# STM32H573 register map
File version: 1.8
CPU: CM33 r0p0, little endian, MPU, FPU, 4 interrupt priority bits
Registers are 32-bit, read-write, reset 0x0 unless marked. A register's access mark holds for its fields unless they carry their own. Offsets are from the block's base; [hi:lo] are bit positions; {n}, {i} and the like mark numbered series; 'fields as' and 'values as' point back to an identical list.

## FMC — Flexible memory controller
Base 0x47000400
Same registers: SEC_FMC 0x57000400
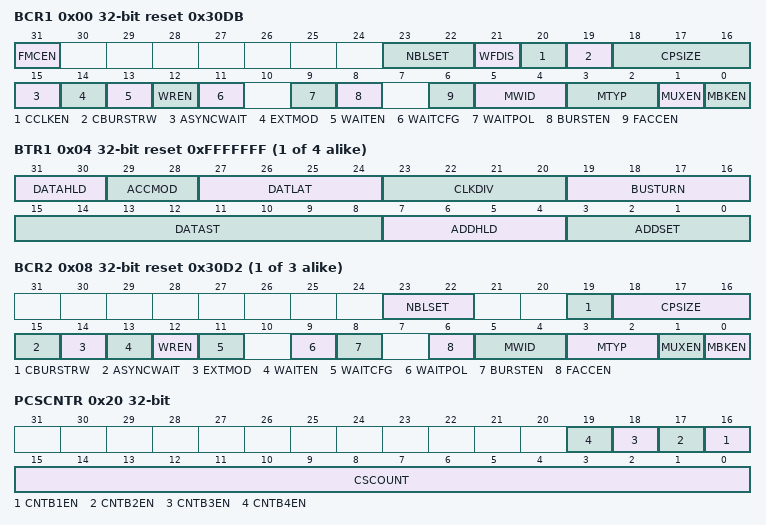
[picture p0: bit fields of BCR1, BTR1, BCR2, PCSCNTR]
0x00 BCR1 reset 0x30DB — SRAM/NOR-Flash chip-select control register for bank 1
  [31] FMCEN — FMC controller enable This bit enables or disables the FMC controller. Note: The FMCEN bit of the FMC_BCR2..4 registers is don't care. It is only enabled through the FMC_BCR1 register.
    0=Disabled (Disable the FMC controller); 1=Enabled (Enable the FMC controller)
  [23:22] NBLSET — Byte lane (NBL) setup These bits configure the NBL setup timing from NBLx low to chip select NEx low.
  [21] WFDIS — Write FIFO disable This bit disables the Write FIFO used by the FMC controller. Note: The WFDIS bit of the FMC_BCR2..4 registers is don't care. It is only enabled through the FMC_BCR1 register.
    0=Enabled (Write FIFO enabled); 1=Disabled (Write FIFO disabled)
  [20] CCLKEN — Continuous clock enable This bit enables the FMC_CLK clock output to external memory devices. Note: The CCLKEN bit of the FMC_BCR2..4 registers is don't care. It is only enabled through the FMC_BCR1 register. Bank 1 must be configured in Synchronous mode to generate the FMC_CLK continuous clock. Note: If CCLKEN bit is set, the FMC_CLK clock ratio is specified by CLKDIV value in the FMC_BTR1 register. CLKDIV in FMC_BWTR1 is don't care. Note: If the Synchronous mode is used and CCLKEN bit is set, the synchronous memories connected to other banks than Bank 1 are clocked by the same clock (the CLKDIV value in the FMC_BTR2..4 and FMC_BWTR2..4 registers for other banks has no effect.)
    0=Disabled (The FMC_CLK is generated continuously during asynchronous and synchronous access. The FMC_CLK clock is activated when the CCLKEN is set); 1=Enabled (The FMC_CLK is only generated during the synchronous memory access (read/write transaction))
  [19] CBURSTRW — Write burst enable For PSRAM (CRAM) operating in Burst mode, the bit enables synchronous accesses during write operations. The enable bit for synchronous read accesses is the BURSTEN bit in the FMC_BCRx register.
    0=Disabled (Write operations are always performed in asynchronous mode); 1=Enabled (Write operations are performed in synchronous mode)
  [18:16] CPSIZE — CRAM page size These are used for CellularRAM 1.5 which does not allow burst access to cross the address boundaries between pages. When these bits are configured, the FMC controller splits automatically the burst access when the memory page size is reached (refer to memory datasheet for page size). Others: reserved
    0=No burst split when crossing page boundary; 1=Bytes128 (128 bytes CRAM page size); 2=Bytes256 (256 bytes CRAM page size); 3=Bytes512 (512 bytes CRAM page size); 4=Bytes1024 (1024 bytes CRAM page size)
  [15] ASYNCWAIT — Wait signal during asynchronous transfers This bit enables/disables the FMC to use the wait signal even during an asynchronous protocol.
    0=Disabled (Wait signal not used in asynchronous mode); 1=Enabled (Wait signal used even in asynchronous mode)
  [14] EXTMOD — Extended mode enable This bit enables the FMC to program the write timings for non multiplexed asynchronous accesses inside the FMC_BWTR register, thus resulting in different timings for read and write operations. Note: When the Extended mode is disabled, the FMC can operate in mode 1 or mode 2 as follows: Mode 1 is the default mode when the SRAM/PSRAM memory type is selected (MTYP = 0x0 or 0x01) Mode 2 is the default mode when the NOR memory type is selected (MTYP = 0x10).
    0=Disabled (Values inside the FMC_BWTR are not taken into account); 1=Enabled (Values inside the FMC_BWTR are taken into account)
  [13] WAITEN — Wait enable bit This bit enables/disables wait-state insertion via the NWAIT signal when accessing the memory in Synchronous mode.
    0=Disabled (Values inside the FMC_BWTR are taken into account); 1=Enabled (NWAIT signal enabled)
  [12] WREN — Write enable bit This bit indicates whether write operations are enabled/disabled in the bank by the FMC.
    0=Disabled (Write operations disabled for the bank by the FMC); 1=Enabled (Write operations enabled for the bank by the FMC)
  [11] WAITCFG — Wait timing configuration The NWAIT signal indicates whether the data from the memory are valid or if a wait state must be inserted when accessing the memory in Synchronous mode. This configuration bit determines if NWAIT is asserted by the memory one clock cycle before the wait state or during the wait state:
    0=BeforeWaitState (NWAIT signal is active one data cycle before wait state); 1=DuringWaitState (NWAIT signal is active during wait state)
  [9] WAITPOL — Wait signal polarity bit Defines the polarity of the wait signal from memory used for either in Synchronous or Asynchronous mode.
    0=ActiveLow (NWAIT active low); 1=ActiveHigh (NWAIT active high)
  [8] BURSTEN — Burst enable bit This bit enables/disables synchronous accesses during read operations. It is valid only for synchronous memories operating in Burst mode.
    0=Disabled (Burst mode disabled); 1=Enabled (Burst mode enabled)
  [6] FACCEN — Flash access enable Enables NOR Flash memory access operations.
    0=Disabled (Corresponding NOR Flash memory access is disabled); 1=Enabled (Corresponding NOR Flash memory access is enabled)
  [5:4] MWID — Memory data bus width Defines the external memory device width, valid for all type of memories.
    0=Bits8 (Memory data bus width 8 bits); 1=Bits16 (Memory data bus width 16 bits); 2=Bits32 (Memory data bus width 32 bits)
  [3:2] MTYP — Memory type Defines the type of external memory attached to the corresponding memory bank.
    0=SRAM (SRAM memory type); 1=PSRAM (PSRAM (CRAM) memory type); 2=Flash (NOR Flash/OneNAND Flash)
  [1] MUXEN — Address/data multiplexing enable bit When this bit is set, the address and data values are multiplexed on the data bus, valid only with NOR and PSRAM memories:
    0=Disabled (Address/Data non-multiplexed); 1=Enabled (Address/Data multiplexed on databus)
  [0] MBKEN — Memory bank enable bit Enables the memory bank. After reset Bank1 is enabled, all others are disabled. Accessing a disabled bank causes an ERROR on AHB bus.
    0=Disabled (Corresponding memory bank is disabled); 1=Enabled (Corresponding memory bank is enabled)
0x04 BTR{i} (i=1..4; step 0x8) reset 0xFFFFFFF — SRAM/NOR-Flash chip-select timing register for bank {i}
  [31:30] DATAHLD — Data hold phase duration These bits are written by software to define the duration of the data hold phase in HCLK cycles (refer to Figure 21 to Figure 33), used in asynchronous accesses: For read accesses For write accesses
  [29:28] ACCMOD — Access mode Specifies the asynchronous access modes as shown in the timing diagrams. These bits are taken into account only when the EXTMOD bit in the FMC_BCRx register is 1.
    0=A (Access mode A); 1=B (Access mode B); 2=C (Access mode C); 3=D (Access mode D)
  [27:24] DATLAT — (see note below bit descriptions): Data latency for synchronous memory For synchronous access with read/write Burst mode enabled (BURSTEN / CBURSTRW bits set), defines the number of memory clock cycles (+2) to issue to the memory before reading/writing the first data: This timing parameter is not expressed in HCLK periods, but in FMC_CLK periods. For asynchronous access, this value is don't care.
  [23:20] CLKDIV range 1..15 — Clock divide ratio (for FMC_CLK signal) Defines the period of FMC_CLK clock output signal, expressed in number of HCLK cycles: In asynchronous NOR Flash, SRAM or PSRAM accesses, this value is don't care. Note: Refer to Section 5.6.5: Synchronous transactions for FMC_CLK divider ratio formula)
  [19:16] BUSTURN — Bus turnaround phase duration These bits are written by software to add a delay at the end of current read or write transaction to next transaction on the same bank. This delay allows to match the minimum time between consecutive transactions (t sub EHEL /sub from NEx high to NEx low) and the maximum time needed by the memory to free the data bus after a read access (t sub EHQZ /sub , chip enable high to output Hi-Z). This delay is recommended for mode D and muxed mode. For non-muxed memory, the bus turnaround delay can be set to minimum value. (BUSTURN + 1)HCLK period greater than or equal max(t sub EHEL /sub min, t sub EHQZ /sub max) For FRAM memories, the bus turnaround delay should be configured to match the minimum tPC (precharge time) timings. The bus turnaround delay is inserted between any consecutive transactions on the same bank (read/read, write/write, read/write and write/read) to match the tPC memory timing. The chip select is toggling between any consecutive accesses. (BUSTURN + 1)HCLK period greater than or equal t sub PC /sub min ...
  [15:8] DATAST range 1..255 — Data-phase duration These bits are written by software to define the duration of the data phase (refer to Figure 21 to Figure 33), used in asynchronous accesses: ... For each memory type and access mode data-phase duration, refer to the respective figure (Figure 21 to Figure 33). Example: Mode 1, write access, DATAST=1: Data-phase duration= DATAST+1 = 2 HCLK clock cycles. Note: In synchronous accesses, this value is don't care.
  [7:4] ADDHLD range 1..15 — Address-hold phase duration These bits are written by software to define the duration of the address hold phase (refer to Figure 21 to Figure 33), used in mode D or multiplexed accesses: ... For each access mode address-hold phase duration, refer to the respective figure (Figure 21 to Figure 33). Note: In synchronous accesses, this value is not used, the address hold phase is always 1 memory clock period duration.
  [3:0] ADDSET — Address setup phase duration These bits are written by software to define the duration of the address setup phase (refer to Figure 21 to Figure 33), used in SRAMs, ROMs, asynchronous NOR Flash and PSRAM: ... For each access mode address setup phase duration, refer to the respective figure (Figure 21 to Figure 33). Note: In synchronous accesses, this value is don't care. Note: In Muxed mode or mode D, the minimum value for ADDSET is 1. Note: In mode 1 and PSRAM memory, the minimum value for ADDSET is 1.
0x08 BCR{i} (i=2..4; step 0x8) reset 0x30D2 — SRAM/NOR-Flash chip-select control register for bank {i}
  [23:22] NBLSET — Byte lane (NBL) setup These bits configure the NBL setup timing from NBLx low to chip select NEx low.
  [19] CBURSTRW — Write burst enable For PSRAM (CRAM) operating in Burst mode, the bit enables synchronous accesses during write operations. The enable bit for synchronous read accesses is the BURSTEN bit in the FMC_BCRx register.
    values as BCR1.CBURSTRW
  [18:16] CPSIZE — CRAM page size These are used for CellularRAM 1.5 which does not allow burst access to cross the address boundaries between pages. When these bits are configured, the FMC controller splits automatically the burst access when the memory page size is reached (refer to memory datasheet for page size). Others: reserved
    values as BCR1.CPSIZE
  [15] ASYNCWAIT — Wait signal during asynchronous transfers This bit enables/disables the FMC to use the wait signal even during an asynchronous protocol.
    values as BCR1.ASYNCWAIT
  [14] EXTMOD — Extended mode enable This bit enables the FMC to program the write timings for non multiplexed asynchronous accesses inside the FMC_BWTR register, thus resulting in different timings for read and write operations. Note: When the Extended mode is disabled, the FMC can operate in mode 1 or mode 2 as follows: Mode 1 is the default mode when the SRAM/PSRAM memory type is selected (MTYP = 0x0 or 0x01) Mode 2 is the default mode when the NOR memory type is selected (MTYP = 0x10).
    values as BCR1.EXTMOD
  [13] WAITEN — Wait enable bit This bit enables/disables wait-state insertion via the NWAIT signal when accessing the memory in Synchronous mode.
    values as BCR1.WAITEN
  [12] WREN — Write enable bit This bit indicates whether write operations are enabled/disabled in the bank by the FMC.
    values as BCR1.WREN
  [11] WAITCFG — Wait timing configuration The NWAIT signal indicates whether the data from the memory are valid or if a wait state must be inserted when accessing the memory in Synchronous mode. This configuration bit determines if NWAIT is asserted by the memory one clock cycle before the wait state or during the wait state:
    values as BCR1.WAITCFG
  [9] WAITPOL — Wait signal polarity bit Defines the polarity of the wait signal from memory used for either in Synchronous or Asynchronous mode.
    values as BCR1.WAITPOL
  [8] BURSTEN — Burst enable bit This bit enables/disables synchronous accesses during read operations. It is valid only for synchronous memories operating in Burst mode.
    values as BCR1.BURSTEN
  [6] FACCEN — Flash access enable Enables NOR Flash memory access operations.
    values as BCR1.FACCEN
  [5:4] MWID — Memory data bus width Defines the external memory device width, valid for all type of memories.
    values as BCR1.MWID
  [3:2] MTYP — Memory type Defines the type of external memory attached to the corresponding memory bank.
    values as BCR1.MTYP
  [1] MUXEN — Address/data multiplexing enable bit When this bit is set, the address and data values are multiplexed on the data bus, valid only with NOR and PSRAM memories:
    values as BCR1.MUXEN
  [0] MBKEN — Memory bank enable bit Enables the memory bank. After reset Bank1 is enabled, all others are disabled. Accessing a disabled bank causes an ERROR on AHB bus.
    values as BCR1.MBKEN
0x20 PCSCNTR — PSRAM chip select counter register
  [n+15] CNTB{n}EN (n=1..4) — Counter Bank {n} enable
  [15:0] CSCOUNT — Chip select counter. These bits are written by software to define the maximum chip select low pulse duration. It is expressed in FMC_CLK cycles for synchronous accesses and in HCLK cycles for asynchronous accesses. The counter is disabled if the programmed value is 0.
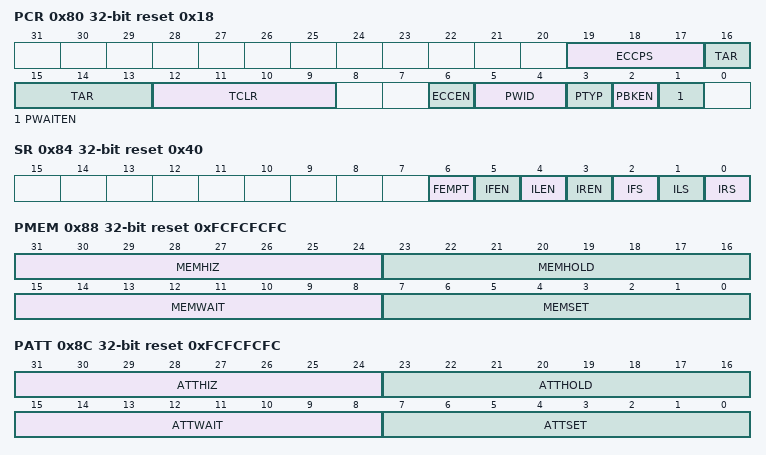
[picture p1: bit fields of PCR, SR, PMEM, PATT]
0x80 PCR access not given reset 0x18 — NAND Flash control registers
  [19:17] ECCPS rw — ECC page size Defines the page size for the extended ECC:
    0=Bytes256 (ECC page size 256 bytes); 1=Bytes512 (ECC page size 512 bytes); 2=Bytes1024 (ECC page size 1024 bytes); 3=Bytes2048 (ECC page size 2048 bytes); 4=Bytes4096 (ECC page size 4096 bytes); 5=Bytes8192 (ECC page size 8192 bytes)
  [16:13] TAR — ALE to RE delay Sets time from ALE low to RE low in number of AHB clock cycles (HCLK). Time is: t_ar = (TAR + SET + 2) THCLK where THCLK is the HCLK clock period Note: SET is MEMSET or ATTSET according to the addressed space.
  [12:9] TCLR rw — CLE to RE delay Sets time from CLE low to RE low in number of AHB clock cycles (HCLK). Time is t_clr = (TCLR + SET + 2) THCLK where THCLK is the HCLK clock period Note: SET is MEMSET or ATTSET according to the addressed space.
  [6] ECCEN rw — ECC computation logic enable bit
    0=Disabled (ECC logic is disabled and reset); 1=Enabled (ECC logic is enabled)
  [5:4] PWID rw — Data bus width Defines the external memory device width.
    0=Bits8 (External memory device width 8 bits); 1=Bits16 (External memory device width 16 bits)
  [3] PTYP rw — Memory type Defines the type of device attached to the corresponding memory bank:
    1=NANDFlash
  [2] PBKEN rw — NAND Flash memory bank enable bit Enables the memory bank. Accessing a disabled memory bank causes an ERROR on AHB bus
    values as BCR1.MBKEN
  [1] PWAITEN rw — Wait feature enable bit Enables the Wait feature for the NAND Flash memory bank:
    0=Disabled (Wait feature disabled); 1=Enabled (Wait feature enabled)
0x84 SR access per field reset 0x40 — FIFO status and interrupt register
  [6] FEMPT ro — FIFO empty Read-only bit that provides the status of the FIFO
    0=NotEmpty (FIFO not empty); 1=Empty (FIFO empty)
  [5] IFEN rw — Interrupt falling edge detection enable bit
    0=Disabled (Interrupt falling edge detection request disabled); 1=Enabled (Interrupt falling edge detection request enabled)
  [4] ILEN rw — Interrupt high-level detection enable bit
    0=Disabled (Interrupt high-level detection request disabled); 1=Enabled (Interrupt high-level detection request enabled)
  [3] IREN rw — Interrupt rising edge detection enable bit
    0=Disabled (Interrupt rising edge detection request disabled); 1=Enabled (Interrupt rising edge detection request enabled)
  [2] IFS rw — Interrupt falling edge status The flag is set by hardware and reset by software. Note: If this bit is written by software to 1 it is set.
    0=DidNotOccur (Interrupt falling edge did not occur); 1=Occurred (Interrupt falling edge occurred)
  [1] ILS rw — Interrupt high-level status The flag is set by hardware and reset by software.
    0=DidNotOccur (Interrupt high-level did not occur); 1=Occurred (Interrupt high-level occurred)
  [0] IRS rw — Interrupt rising edge status The flag is set by hardware and reset by software. Note: If this bit is written by software to 1 it is set.
    0=DidNotOccur (Interrupt rising edge did not occur); 1=Occurred (Interrupt rising edge occurred)
0x88 PMEM reset 0xFCFCFCFC — Common memory space timing register
  [31:24] MEMHIZ range 0..254 — Common memory x data bus Hi-Z time Defines the number of HCLK clock cycles during which the data bus is kept Hi-Z after the start of a NAND Flash write access to common memory space on socket. This is only valid for write transactions:
  [23:16] MEMHOLD range 1..254 — Common memory hold time Defines the number of HCLK clock cycles for write access and HCLK (+2) clock cycles for read access during which the address is held (and data for write accesses) after the command is deasserted (NWE, NOE), for NAND Flash read or write access to common memory space on socket x:
  [15:8] MEMWAIT range 1..254 — Common memory wait time Defines the minimum number of HCLK (+1) clock cycles to assert the command (NWE, NOE), for NAND Flash read or write access to common memory space on socket. The duration of command assertion is extended if the wait signal (NWAIT) is active (low) at the end of the programmed value of HCLK:
  [7:0] MEMSET range 0..254 — Common memory x setup time Defines the number of HCLK (+1) clock cycles to set up the address before the command assertion (NWE, NOE), for NAND Flash read or write access to common memory space on socket x:
0x8C PATT reset 0xFCFCFCFC — Attribute memory space timing register
  [31:24] ATTHIZ range 0..254 — Attribute memory data bus Hi-Z time Defines the number of HCLK clock cycles during which the data bus is kept in Hi-Z after the start of a NAND Flash write access to attribute memory space on socket. Only valid for writ transaction:
  [23:16] ATTHOLD range 1..254 — Attribute memory hold time Defines the number of HCLK clock cycles for write access and HCLK (+2) clock cycles for read access during which the address is held (and data for write access) after the command deassertion (NWE, NOE), for NAND Flash read or write access to attribute memory space on socket:
  [15:8] ATTWAIT range 1..254 — Attribute memory wait time Defines the minimum number of HCLK (+1) clock cycles to assert the command (NWE, NOE), for NAND Flash read or write access to attribute memory space on socket x. The duration for command assertion is extended if the wait signal (NWAIT) is active (low) at the end of the programmed value of HCLK:
  [7:0] ATTSET range 0..254 — Attribute memory setup time Defines the number of HCLK (+1) clock cycles to set up address before the command assertion (NWE, NOE), for NAND Flash read or write access to attribute memory space on socket:
0x94 ECCR ro — ECC result registers
  [31:0] ECC — ECC result This field contains the value computed by the ECC computation logic. Table 99 describes the contents of these bitfields.
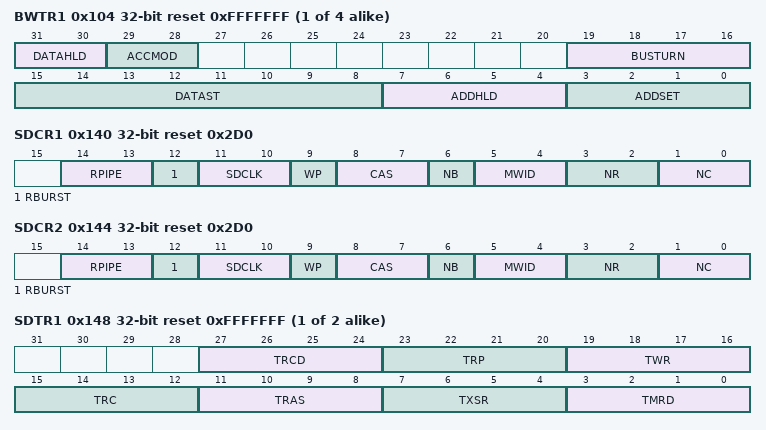
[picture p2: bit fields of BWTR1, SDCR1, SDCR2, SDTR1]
{0xFC+8i} BWTR{i} (i=1..4) reset 0xFFFFFFF — SRAM/NOR-Flash write timing registers {i}
  [31:30] DATAHLD — Data hold phase duration These bits are written by software to define the duration of the data hold phase in HCLK cycles (refer to Figure 21 to Figure 33), used in asynchronous write accesses:
  [29:28] ACCMOD — Access mode. Specifies the asynchronous access modes as shown in the next timing diagrams.These bits are taken into account only when the EXTMOD bit in the FMC_BCRx register is 1.
    values as BTR{i}.ACCMOD
  [19:16] BUSTURN — Bus turnaround phase duration These bits are written by software to add a delay at the end of current write transaction to next transaction on the same bank. For FRAM memories, the bus turnaround delay should be configured to match the minimum t sub PC /sub (precharge time) timings. The bus turnaround delay is inserted between any consecutive transactions on the same bank (read/read, write/write, read/write and write/read). The chip select is toggling between any consecutive accesses. (BUSTURN + 1)HCLK period greater than or equal tPC min ...
  [15:8] DATAST range 1..255 — Data-phase duration. These bits are written by software to define the duration of the data phase (refer to Figure 21 to Figure 33), used in asynchronous SRAM, PSRAM and NOR Flash memory accesses: ...
  [7:4] ADDHLD range 1..15 — Address-hold phase duration. These bits are written by software to define the duration of the address hold phase (refer to Figure 30 to Figure 33), used in asynchronous multiplexed accesses: ... Note: In synchronous NOR Flash accesses, this value is not used, the address hold phase is always 1 Flash clock period duration.
  [3:0] ADDSET — Address setup phase duration. These bits are written by software to define the duration of the address setup phase in HCLK cycles (refer to Figure 21 to Figure 33), used in asynchronous accesses: ... Note: In synchronous accesses, this value is not used, the address setup phase is always 1 Flash clock period duration. In muxed mode, the minimum ADDSET value is 1.
0x140 SDCR1 reset 0x2D0 — SDRAM control registers 1
  [14:13] RPIPE — Read pipe These bits define the delay, in clock cycles, for reading data after CAS latency. Note: The corresponding bits in the FMC_SDCR2 register is read only.
    0=NoDelay (No clock cycle delay); 1=Clocks1 (One clock cycle delay); 2=Clocks2 (Two clock cycles delay)
  [12] RBURST — Burst read This bit enables Burst read mode. The SDRAM controller anticipates the next read commands during the CAS latency and stores data in the Read FIFO. Note: The corresponding bit in the FMC_SDCR2 register is don't care.
    0=Disabled (Single read requests are not managed as bursts); 1=Enabled (Single read requests are always managed as bursts)
  [11:10] SDCLK — SDRAM clock configuration These bits define the SDRAM clock period for both SDRAM banks and allow disabling the clock before changing the frequency. In this case the SDRAM must be re-initialized. Note: The corresponding bits in the FMC_SDCR2 register are don't care.
    0=Disabled (SDCLK clock disabled); 2=Div2 (SDCLK period = 2 x HCLK period); 3=Div3 (SDCLK period = 3 x HCLK period)
  [9] WP — Write protection This bit enables write mode access to the SDRAM bank.
    0=Disabled (Write accesses allowed); 1=Enabled (Write accesses ignored)
  [8:7] CAS — CAS Latency This bits sets the SDRAM CAS latency in number of memory clock cycles
    1=Clocks1 (1 cycle); 2=Clocks2 (2 cycles); 3=Clocks3 (3 cycles)
  [6] NB — Number of internal banks This bit sets the number of internal banks.
    0=Two internal Banks; 1=Four internal Banks
  [5:4] MWID — Memory data bus width. These bits define the memory device width.
    values as BCR1.MWID
  [3:2] NR — Number of row address bits These bits define the number of bits of a row address.
    0=Bits11 (11 bits); 1=Bits12 (12 bits); 2=Bits13 (13 bits)
  [1:0] NC — Number of column address bits These bits define the number of bits of a column address.
    {v}=Bits{v+8} ({v+8} bits) (v=0..3)
0x144 SDCR2 reset 0x2D0 — SDRAM control registers 2
  fields as SDCR1
{0x144+4i} SDTR{i} (i=1..2) reset 0xFFFFFFF — SDRAM timing registers {i}
  [27:24] TRCD — Row to column delay These bits define the delay between the Activate command and a Read/Write command in number of memory clock cycles. ....
  [23:20] TRP — Row precharge delay These bits define the delay between a Precharge command and another command in number of memory clock cycles. The TRP timing is only configured in the FMC_SDTR1 register. If two SDRAM devices are used, the TRP must be programmed with the timing of the slowest device. .... Note: The corresponding bits in the FMC_SDTR2 register are don't care.
  [19:16] TWR — Recovery delay These bits define the delay between a Write and a Precharge command in number of memory clock cycles. .... Note: TWR must be programmed to match the write recovery time (t sub WR /sub ) defined in the SDRAM datasheet, and to guarantee that: Note: TWR greater than or equal TRAS TRCD and TWR greater than or equalTRC TRCD TRP Note: Example: TRAS= 4 cycles, TRCD= 2 cycles. So, TWR = 2 cycles. TWR must be programmed to 0x1. Note: If two SDRAM devices are used, the FMC_SDTR1 and FMC_SDTR2 must be programmed with the same TWR timing corresponding to the slowest SDRAM device. Note: If only one SDRAM device is used, the TWR timing must be kept at reset value (0xF) for the not used bank.
  [15:12] TRC — Row cycle delay These bits define the delay between the Refresh command and the Activate command, as well as the delay between two consecutive Refresh commands. It is expressed in number of memory clock cycles. The TRC timing is only configured in the FMC_SDTR1 register. If two SDRAM devices are used, the TRC must be programmed with the timings of the slowest device. .... Note: TRC must match the TRC and TRFC (Auto Refresh period) timings defined in the SDRAM device datasheet. Note: The corresponding bits in the FMC_SDTR2 register are don't care.
  [11:8] TRAS — Self refresh time These bits define the minimum Self-refresh period in number of memory clock cycles. ....
  [7:4] TXSR — Exit Self-refresh delay These bits define the delay from releasing the Self-refresh command to issuing the Activate command in number of memory clock cycles. .... Note: If two SDRAM devices are used, the FMC_SDTR1 and FMC_SDTR2 must be programmed with the same TXSR timing corresponding to the slowest SDRAM device.
  [3:0] TMRD — Load Mode Register to Active These bits define the delay between a Load Mode Register command and an Active or Refresh command in number of memory clock cycles. ....
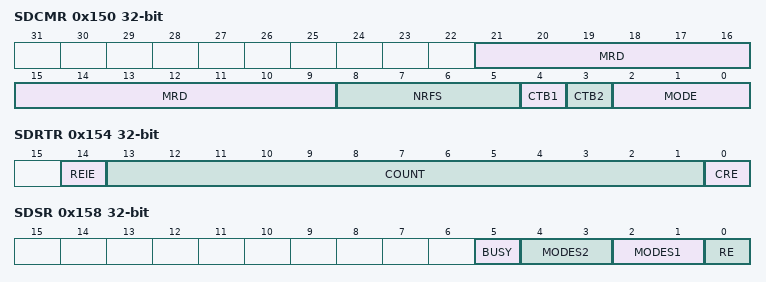
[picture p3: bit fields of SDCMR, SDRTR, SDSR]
0x150 SDCMR — SDRAM Command Mode register
  [21:9] MRD — Mode Register definition This 13-bit field defines the SDRAM Mode Register content. The Mode Register is programmed using the Load Mode Register command.
  [8:5] NRFS — Number of Auto-refresh These bits define the number of consecutive Auto-refresh commands issued when MODE = '011'. ....
  [4] CTB1 — Command Target Bank 1 This bit indicates whether the command will be issued to SDRAM Bank 1 or not.
    0=NotIssued (Command not issued to SDRAM Bank 1); 1=Issued (Command issued to SDRAM Bank 1)
  [3] CTB2 — Command Target Bank 2 This bit indicates whether the command will be issued to SDRAM Bank 2 or not.
    values as CTB1
  [2:0] MODE — Command mode These bits define the command issued to the SDRAM device. Note: When a command is issued, at least one Command Target Bank bit ( CTB1 or CTB2) must be set otherwise the command will be ignored. Note: If two SDRAM banks are used, the Auto-refresh and PALL command must be issued simultaneously to the two devices with CTB1 and CTB2 bits set otherwise the command will be ignored. Note: If only one SDRAM bank is used and a command is issued with it's associated CTB bit set, the other CTB bit of the the unused bank must be kept to 0.
    0=Normal Mode; 1=ClockConfigurationEnable; 2=PALL (PALL (All Bank Precharge) command); 3=AutoRefreshCommand; 4=LoadModeRegister (Load Mode Resgier); 5=SelfRefreshCommand; 6=PowerDownCommand
0x154 SDRTR access per field — SDRAM refresh timer register
  [14] REIE rw — RES Interrupt Enable
    0=Disabled (Interrupt is disabled); 1=Enabled (Interrupt is generated if RE = 1)
  [13:1] COUNT rw — Refresh Timer Count This 13-bit field defines the refresh rate of the SDRAM device. It is expressed in number of memory clock cycles. It must be set at least to 41 SDRAM clock cycles (0x29). Refresh rate = (COUNT + 1) x SDRAM frequency clock COUNT = (SDRAM refresh period / Number of rows) 20
  [0] CRE wo — Clear Refresh error flag This bit is used to clear the Refresh Error Flag (RE) in the Status Register.
    1=Clear (Refresh Error Flag is cleared)
0x158 SDSR ro — SDRAM status register
  [5] BUSY — Busy status This bit defines the status of the SDRAM controller after a Command Mode request 1; SDRAM Controller is not ready to accept a new request
    0=NotBusy (SDRAM Controller is ready to accept a new request); 1=Busy (SDRAM Controller is not ready to accept a new request)
  [4:3] MODES2 — Status Mode for Bank 2 This bit defines the Status Mode of SDRAM Bank 2.
    0=Normal Mode; 1=Self-refresh mode; 2=Power-down mode
  [2:1] MODES1 — Status Mode for Bank 1 This bit defines the Status Mode of SDRAM Bank 1.
    0=Normal Mode; 1=Self-refresh mode; 2=Power-down mode
  [0] RE — Refresh error flag An interrupt is generated if REIE = 1 and RE = 1
    0=NoError (No refresh error has been detected); 1=Error (A refresh error has been detected)
